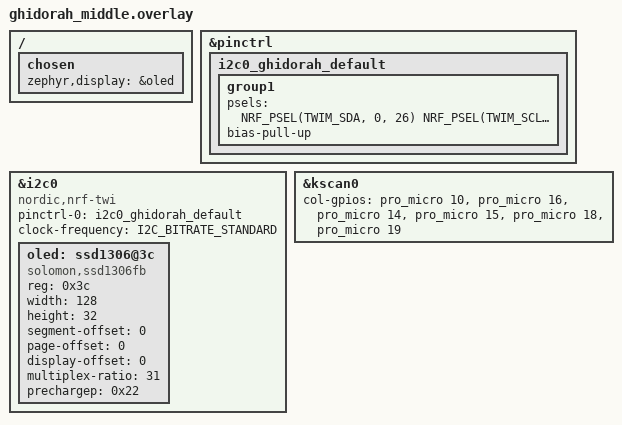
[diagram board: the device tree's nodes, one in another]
/*
 * Ghidorah – Middle (Central) Shield
 * nice!nano v2 + SSD1306 128x32 OLED
 */

/ {
    chosen {
        zephyr,display = &oled;
    };
};

/* -------------------- PINCTRL -------------------- */

&pinctrl {
    i2c0_ghidorah_default: i2c0_ghidorah_default {
        group1 {
            psels = <
                NRF_PSEL(TWIM_SDA, 0, 26)
                NRF_PSEL(TWIM_SCL, 0, 27)
            >;
            bias-pull-up;
        };
    };
};

/* -------------------- I2C BUS -------------------- */

&i2c0 {
    compatible = "nordic,nrf-twi";
    status = "okay";

    pinctrl-0 = <&i2c0_ghidorah_default>;
    pinctrl-names = "default";

    clock-frequency = <I2C_BITRATE_STANDARD>;

    oled: ssd1306@3c {
        compatible = "solomon,ssd1306fb";
        reg = <0x3c>;

        width = <128>;
        height = <32>;

        segment-offset = <0>;
        page-offset = <0>;
        display-offset = <0>;
        multiplex-ratio = <31>;

        prechargep = <0x22>;

        status = "okay";
    };
};

&kscan0 {
    col-gpios =
        <&pro_micro 10 GPIO_ACTIVE_HIGH>,
        <&pro_micro 16 GPIO_ACTIVE_HIGH>,
        <&pro_micro 14 GPIO_ACTIVE_HIGH>,
        <&pro_micro 15 GPIO_ACTIVE_HIGH>,
        <&pro_micro 18 GPIO_ACTIVE_HIGH>,
        <&pro_micro 19 GPIO_ACTIVE_HIGH>;
};
